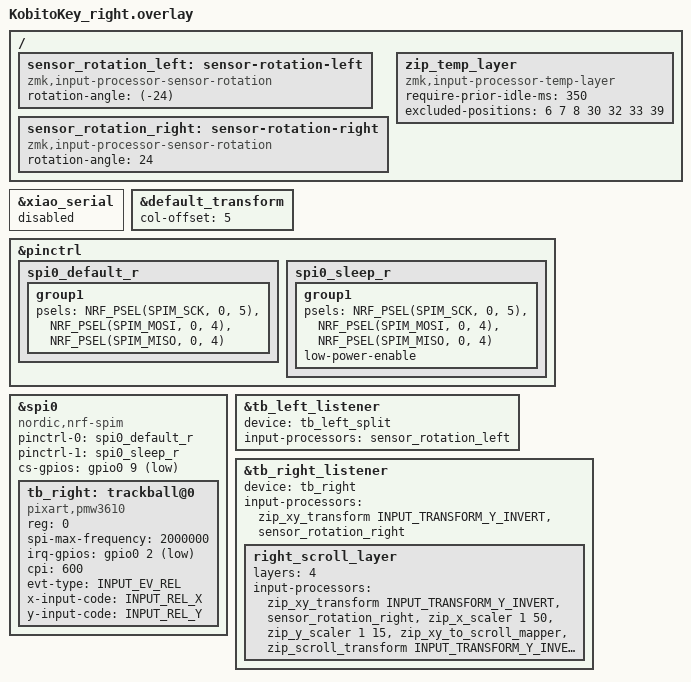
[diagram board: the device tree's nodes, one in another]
#include <zephyr/dt-bindings/pinctrl/nrf-pinctrl.h>
#include "kobitokey.dtsi"
#include <input/processors.dtsi>
#include <input/processors/sensor_rotation.dtsi>

&xiao_serial { status = "disabled"; };

/* 列オフセット */
&default_transform { col-offset = <5>; };

&pinctrl {
    spi0_default_r: spi0_default_r { group1 {
        psels = <NRF_PSEL(SPIM_SCK,  0, 5)>,
                <NRF_PSEL(SPIM_MOSI, 0, 4)>,
                <NRF_PSEL(SPIM_MISO, 0, 4)>;
    }; };
    spi0_sleep_r: spi0_sleep_r { group1 {
        psels = <NRF_PSEL(SPIM_SCK,  0, 5)>,
                <NRF_PSEL(SPIM_MOSI, 0, 4)>,
                <NRF_PSEL(SPIM_MISO, 0, 4)>;
        low-power-enable;
    }; };
};

&spi0 {
    status = "okay";
    compatible = "nordic,nrf-spim";
    pinctrl-0 = <&spi0_default_r>;
    pinctrl-1 = <&spi0_sleep_r>;
    pinctrl-names = "default", "sleep";
    cs-gpios = <&gpio0 9 GPIO_ACTIVE_LOW>;

    tb_right: trackball@0 {
        status = "okay";
        compatible = "pixart,pmw3610";
        reg = <0>;
        spi-max-frequency = <2000000>;
        irq-gpios = <&gpio0 2 (GPIO_ACTIVE_LOW | GPIO_PULL_UP)>;
        cpi = <600>;
        
        evt-type = <INPUT_EV_REL>;
        x-input-code = <INPUT_REL_X>;
        y-input-code = <INPUT_REL_Y>;
    };
};


/* Both input listeners run on the RIGHT central half. */
/ {
    sensor_rotation_left: sensor-rotation-left {
        compatible = "zmk,input-processor-sensor-rotation";
        status = "okay";
        #input-processor-cells = <0>;
        rotation-angle = <(-24)>;
    };

    sensor_rotation_right: sensor-rotation-right {
        compatible = "zmk,input-processor-sensor-rotation";
        status = "okay";
        #input-processor-cells = <0>;
        rotation-angle = <24>;
    };

    /omit-if-no-ref/ zip_temp_layer: zip_temp_layer {
        compatible = "zmk,input-processor-temp-layer";
        #input-processor-cells = <2>;
        require-prior-idle-ms = <350>;
    };
};

/* Events received from the LEFT peripheral. No coordinate changes on the peripheral. */
&tb_left_listener {
    status = "okay";
    device = <&tb_left_split>;
    input-processors = <&sensor_rotation_left>;
};

/* Local RIGHT PMW3610 (no split BLE hop). Preserve Y inversion from old right-split. */
&tb_right_listener {
    status = "okay";
    device = <&tb_right>;
    input-processors =
        <&zip_xy_transform INPUT_TRANSFORM_Y_INVERT>,
        <&sensor_rotation_right>;

    /* Preserve existing layer-4 conversion to scroll. */
    right_scroll_layer {
        layers = <4>;
        input-processors =
            <&zip_xy_transform INPUT_TRANSFORM_Y_INVERT>,
            <&sensor_rotation_right>,
            <&zip_x_scaler 1 50>,
            <&zip_y_scaler 1 15>,
            <&zip_xy_to_scroll_mapper>,
            <&zip_scroll_transform INPUT_TRANSFORM_Y_INVERT>;
    };
};

&zip_temp_layer {
    excluded-positions = <
        6
        7
        8
        30
        32
        33
        39
    >;
};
